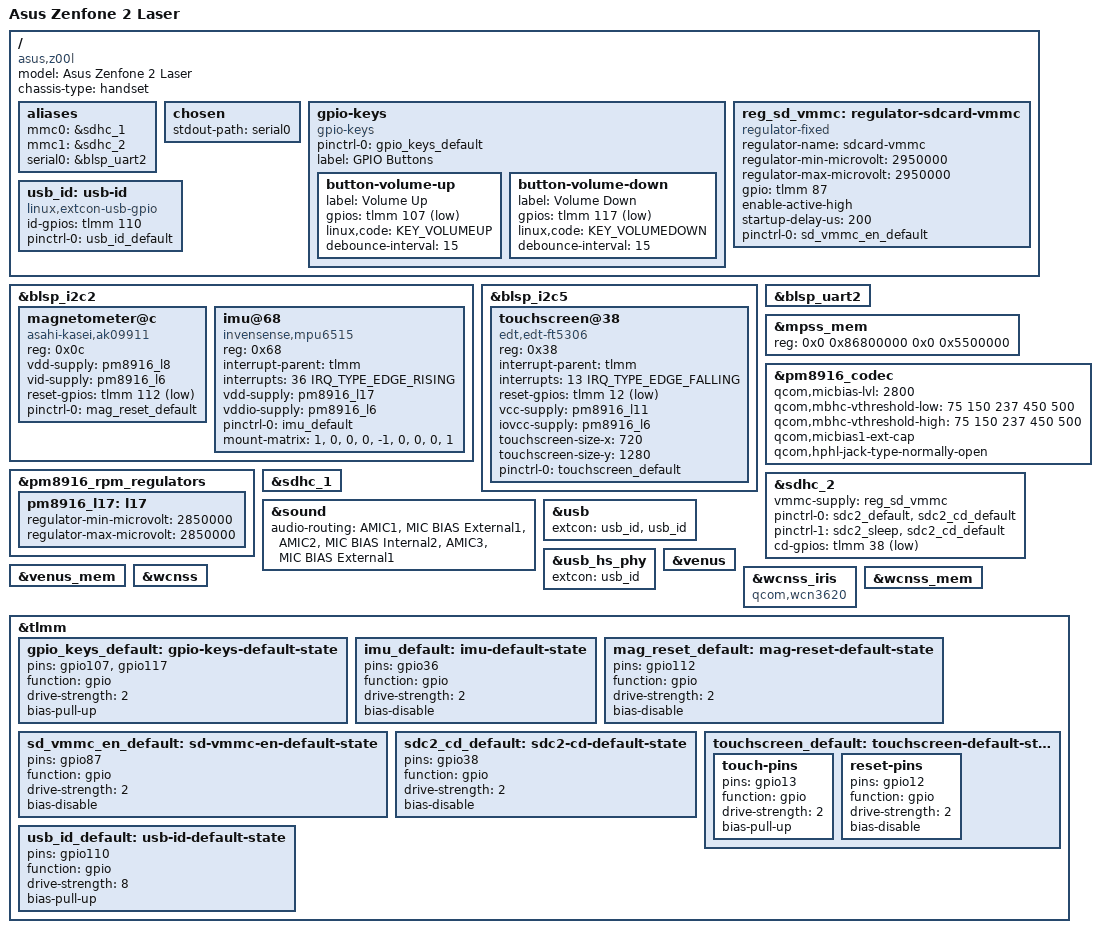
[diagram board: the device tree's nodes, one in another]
// SPDX-License-Identifier: GPL-2.0-only

/dts-v1/;

#include "msm8916-pm8916.dtsi"
#include "msm8916-modem-qdsp6.dtsi"

#include <dt-bindings/gpio/gpio.h>
#include <dt-bindings/input/input.h>
#include <dt-bindings/interrupt-controller/irq.h>

/ {
	model = "Asus Zenfone 2 Laser";
	compatible = "asus,z00l", "qcom,msm8916";
	chassis-type = "handset";

	aliases {
		mmc0 = &sdhc_1; /* eMMC */
		mmc1 = &sdhc_2; /* SD card */
		serial0 = &blsp_uart2;
	};

	chosen {
		stdout-path = "serial0";
	};

	gpio-keys {
		compatible = "gpio-keys";

		pinctrl-names = "default";
		pinctrl-0 = <&gpio_keys_default>;

		label = "GPIO Buttons";

		button-volume-up {
			label = "Volume Up";
			gpios = <&tlmm 107 GPIO_ACTIVE_LOW>;
			linux,code = <KEY_VOLUMEUP>;
			debounce-interval = <15>;
		};

		button-volume-down {
			label = "Volume Down";
			gpios = <&tlmm 117 GPIO_ACTIVE_LOW>;
			linux,code = <KEY_VOLUMEDOWN>;
			debounce-interval = <15>;
		};
	};

	reg_sd_vmmc: regulator-sdcard-vmmc {
		compatible = "regulator-fixed";
		regulator-name = "sdcard-vmmc";
		regulator-min-microvolt = <2950000>;
		regulator-max-microvolt = <2950000>;

		gpio = <&tlmm 87 GPIO_ACTIVE_HIGH>;
		enable-active-high;

		startup-delay-us = <200>;

		pinctrl-names = "default";
		pinctrl-0 = <&sd_vmmc_en_default>;
	};

	usb_id: usb-id {
		compatible = "linux,extcon-usb-gpio";
		id-gpios = <&tlmm 110 GPIO_ACTIVE_HIGH>;
		pinctrl-names = "default";
		pinctrl-0 = <&usb_id_default>;
	};
};

&blsp_i2c2 {
	status = "okay";

	magnetometer@c {
		compatible = "asahi-kasei,ak09911";
		reg = <0x0c>;

		vdd-supply = <&pm8916_l8>;
		vid-supply = <&pm8916_l6>;

		reset-gpios = <&tlmm 112 GPIO_ACTIVE_LOW>;

		pinctrl-names = "default";
		pinctrl-0 = <&mag_reset_default>;
	};

	imu@68 {
		compatible = "invensense,mpu6515";
		reg = <0x68>;

		interrupt-parent = <&tlmm>;
		interrupts = <36 IRQ_TYPE_EDGE_RISING>;

		vdd-supply = <&pm8916_l17>;
		vddio-supply = <&pm8916_l6>;

		pinctrl-names = "default";
		pinctrl-0 = <&imu_default>;

		mount-matrix = "1",  "0", "0",
			       "0", "-1", "0",
			       "0",  "0", "1";
	};
};

&blsp_i2c5 {
	status = "okay";

	touchscreen@38 {
		compatible = "edt,edt-ft5306";
		reg = <0x38>;

		interrupt-parent = <&tlmm>;
		interrupts = <13 IRQ_TYPE_EDGE_FALLING>;

		reset-gpios = <&tlmm 12 GPIO_ACTIVE_LOW>;

		vcc-supply = <&pm8916_l11>;
		iovcc-supply = <&pm8916_l6>;

		touchscreen-size-x = <720>;
		touchscreen-size-y = <1280>;

		pinctrl-names = "default";
		pinctrl-0 = <&touchscreen_default>;
	};
};

&blsp_uart2 {
	status = "okay";
};

&mpss_mem {
	reg = <0x0 0x86800000 0x0 0x5500000>;
};

&pm8916_codec {
	qcom,micbias-lvl = <2800>;
	qcom,mbhc-vthreshold-low = <75 150 237 450 500>;
	qcom,mbhc-vthreshold-high = <75 150 237 450 500>;
	qcom,micbias1-ext-cap;
	qcom,hphl-jack-type-normally-open;
};

&pm8916_rpm_regulators {
	pm8916_l17: l17 {
		regulator-min-microvolt = <2850000>;
		regulator-max-microvolt = <2850000>;
	};
};

&sdhc_1 {
	status = "okay";
};

&sdhc_2 {
	status = "okay";
	vmmc-supply = <&reg_sd_vmmc>;

	pinctrl-names = "default", "sleep";
	pinctrl-0 = <&sdc2_default &sdc2_cd_default>;
	pinctrl-1 = <&sdc2_sleep &sdc2_cd_default>;
	cd-gpios = <&tlmm 38 GPIO_ACTIVE_LOW>;
};

&sound {
	audio-routing =
		"AMIC1", "MIC BIAS External1",
		"AMIC2", "MIC BIAS Internal2",
		"AMIC3", "MIC BIAS External1";
};

&usb {
	status = "okay";
	extcon = <&usb_id>, <&usb_id>;
};

&usb_hs_phy {
	extcon = <&usb_id>;
};

&venus {
	status = "okay";
};

&venus_mem {
	status = "okay";
};

&wcnss {
	status = "okay";
};

&wcnss_iris {
	compatible = "qcom,wcn3620";
};

&wcnss_mem {
	status = "okay";
};

&tlmm {
	gpio_keys_default: gpio-keys-default-state {
		pins = "gpio107", "gpio117";
		function = "gpio";

		drive-strength = <2>;
		bias-pull-up;
	};

	imu_default: imu-default-state {
		pins = "gpio36";
		function = "gpio";

		drive-strength = <2>;
		bias-disable;
	};

	mag_reset_default: mag-reset-default-state {
		pins = "gpio112";
		function = "gpio";

		drive-strength = <2>;
		bias-disable;
	};

	sd_vmmc_en_default: sd-vmmc-en-default-state {
		pins = "gpio87";
		function = "gpio";

		drive-strength = <2>;
		bias-disable;
	};

	sdc2_cd_default: sdc2-cd-default-state {
		pins = "gpio38";
		function = "gpio";
		drive-strength = <2>;
		bias-disable;
	};

	touchscreen_default: touchscreen-default-state {
		touch-pins {
			pins = "gpio13";
			function = "gpio";

			drive-strength = <2>;
			bias-pull-up;
		};

		reset-pins {
			pins = "gpio12";
			function = "gpio";

			drive-strength = <2>;
			bias-disable;
		};
	};

	usb_id_default: usb-id-default-state {
		pins = "gpio110";
		function = "gpio";

		drive-strength = <8>;
		bias-pull-up;
	};
};
